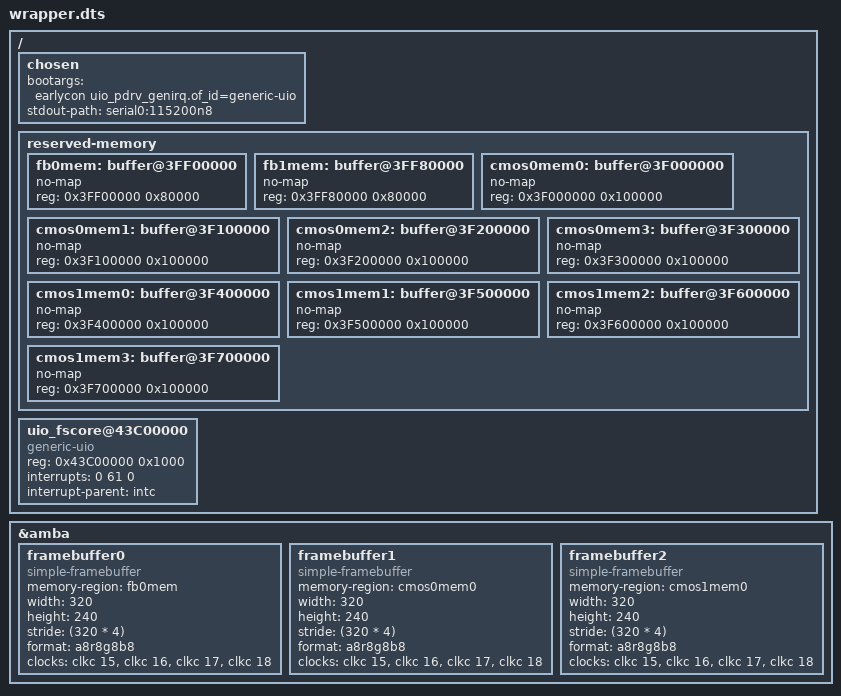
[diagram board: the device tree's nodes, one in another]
/**
 * CAUTION: This file is automatically generated by Xilinx.
 * Version: HSI 2016.3
 * Today is: Thu Nov 24 17:48:26 2016
 */
/include/ "system-top.dts"
/include/ "system.dts"

/ {
	chosen {
		bootargs = "earlycon uio_pdrv_genirq.of_id=generic-uio";
		stdout-path = "serial0:115200n8";
	};

	reserved-memory {
		#address-cells = <1>;
		#size-cells = <1>;
		ranges;

		fb0mem: buffer@3FF00000 {
			no-map;
			reg = <0x3FF00000 0x80000>;
		};

		fb1mem: buffer@3FF80000 {
			no-map;
			reg = <0x3FF80000 0x80000>;
		};

		cmos0mem0: buffer@3F000000 {
			no-map;
			reg = <0x3F000000 0x100000>;
		};

		cmos0mem1: buffer@3F100000 {
			no-map;
			reg = <0x3F100000 0x100000>;
		};

		cmos0mem2: buffer@3F200000 {
			no-map;
			reg = <0x3F200000 0x100000>;
		};

		cmos0mem3: buffer@3F300000 {
			no-map;
			reg = <0x3F300000 0x100000>;
		};

		cmos1mem0: buffer@3F400000 {
			no-map;
			reg = <0x3F400000 0x100000>;
		};

		cmos1mem1: buffer@3F500000 {
			no-map;
			reg = <0x3F500000 0x100000>;
		};

		cmos1mem2: buffer@3F600000 {
			no-map;
			reg = <0x3F600000 0x100000>;
		};

		cmos1mem3: buffer@3F700000 {
			no-map;
			reg = <0x3F700000 0x100000>;
		};
	};

	uio_fscore@43C00000 {
		compatible = "generic-uio";
		reg = < 0x43C00000 0x1000 >;
		interrupts = < 0 61 0 >;
		interrupt-parent = <&intc>;
	};
};

&amba {
	framebuffer0 {
		compatible = "simple-framebuffer";
		//reg = <0x3FF00000 (320 * 240 * 4)>;
		memory-region = <&fb0mem>;
		width = <320>;
		height = <240>;
		stride = <(320 * 4)>;
		format = "a8r8g8b8";
		clocks = <&clkc 15>, <&clkc 16>, <&clkc 17>, <&clkc 18>;
		// lcd-supply = <&reg_dc1sw>;
	};
	framebuffer1 {
		compatible = "simple-framebuffer";
		memory-region = <&cmos0mem0>;
		width = <320>;
		height = <240>;
		stride = <(320 * 4)>;
		format = "a8r8g8b8";
		clocks = <&clkc 15>, <&clkc 16>, <&clkc 17>, <&clkc 18>;
		// lcd-supply = <&reg_dc1sw>;
	};
	framebuffer2 {
		compatible = "simple-framebuffer";
		memory-region = <&cmos1mem0>;
		width = <320>;
		height = <240>;
		stride = <(320 * 4)>;
		format = "a8r8g8b8";
		clocks = <&clkc 15>, <&clkc 16>, <&clkc 17>, <&clkc 18>;
		// lcd-supply = <&reg_dc1sw>;
	};
};
